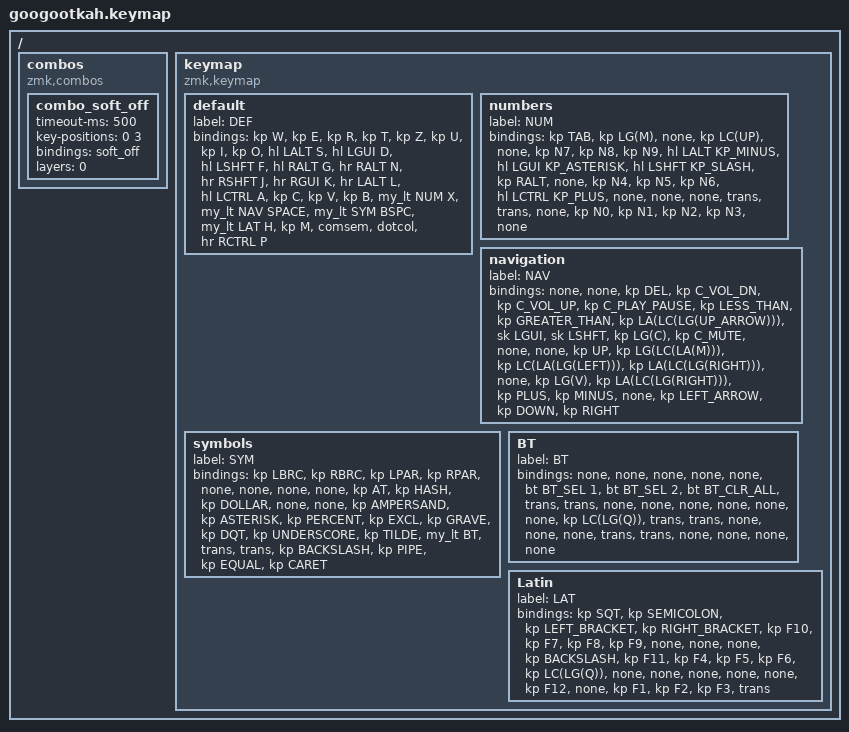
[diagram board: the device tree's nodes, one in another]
#include <behaviors.dtsi>
#include <dt-bindings/zmk/bt.h>
#include <dt-bindings/zmk/keys.h>
#include "googootkah.h"

/*               KEY POSITIONS
 *
 *           ╭──────────────╮          ╭──────────────╮ 
 *           │ 0   1   2   3│          │17  16  15  14│
 *      ╭────╯ 4   5   6   7╰────╮╭────╯21  20  19  18╰────╮
 *      │  8   9  10  11  12  13 ││ 27  26  25  24  23  22 │
 *      ╰────────────────────────╯╰────────────────────────╯
 */

/ {

    combos {
        compatible = "zmk,combos";

        combo_soft_off {
            timeout-ms = <500>;                 
            key-positions = <0 3>;           
            bindings = <&soft_off>;            
            layers = <0>;                      
        };
    };

    keymap {
        compatible = "zmk,keymap";

        default {
            label = "DEF";
            bindings = <
&kp W  &kp E  &kp R  &kp T  &kp Z  &kp U  &kp I  &kp O  &hl LALT S  &hl LGUI D  &hl LSHFT F  &hl RALT G  &hr RALT N  &hr RSHFT J  &hr RGUI K  &hr LALT L  &hl LCTRL A  &kp C  &kp V  &kp B  &my_lt NUM X  &my_lt NAV SPACE  &my_lt SYM BSPC  &my_lt LAT H  &kp M  &comsem  &dotcol  &hr RCTRL P
            >;
        };

        numbers {
            label = "NUM";
            bindings = <
&kp TAB  &kp LG(M)  &none  &kp LC(UP)  &none  &kp N7  &kp N8  &kp N9  &hl LALT KP_MINUS  &hl LGUI KP_ASTERISK  &hl LSHFT KP_SLASH  &kp RALT  &none  &kp N4  &kp N5  &kp N6  &hl LCTRL KP_PLUS  &none  &none  &none  &trans  &trans  &none  &kp N0  &kp N1  &kp N2  &kp N3  &none
            >;
        };

        navigation {
            label = "NAV";
            bindings = <
&none  &none  &kp DEL  &kp C_VOL_DN  &kp C_VOL_UP  &kp C_PLAY_PAUSE  &kp LESS_THAN  &kp GREATER_THAN  &kp LA(LC(LG(UP_ARROW)))  &sk LGUI  &sk LSHFT  &kp LG(C)  &kp C_MUTE  &none  &none  &kp UP  &kp LG(LC(LA(M)))  &kp LC(LA(LG(LEFT)))  &kp LA(LC(LG(RIGHT)))  &none  &kp LG(V)  &kp LA(LC(LG(RIGHT)))  &kp PLUS  &kp MINUS  &none  &kp LEFT_ARROW  &kp DOWN  &kp RIGHT
            >;
        };

        symbols {
            label = "SYM";
            bindings = <
&kp LBRC  &kp RBRC  &kp LPAR  &kp RPAR  &none  &none  &none  &none  &kp AT  &kp HASH  &kp DOLLAR  &none  &none  &kp AMPERSAND  &kp ASTERISK  &kp PERCENT  &kp EXCL  &kp GRAVE  &kp DQT  &kp UNDERSCORE  &kp TILDE  &my_lt BT  &trans  &trans  &kp BACKSLASH  &kp PIPE  &kp EQUAL  &kp CARET
            >;
        };

        BT {
            label = "BT";
            bindings = <
&none  &none  &none  &none  &none  &bt BT_SEL 1  &bt BT_SEL 2  &bt BT_CLR_ALL  &trans  &trans  &none  &none  &none  &none  &none  &none  &kp LC(LG(Q))  &trans  &trans  &none  &none  &none  &trans  &trans  &none  &none  &none  &none
            >;
        };

        Latin {
            label = "LAT";
            bindings = <
&kp SQT  &kp SEMICOLON  &kp LEFT_BRACKET  &kp RIGHT_BRACKET  &kp F10  &kp F7  &kp F8  &kp F9  &none  &none  &none  &kp BACKSLASH  &kp F11  &kp F4  &kp F5  &kp F6  &kp LC(LG(Q))  &none  &none  &none  &none  &none  &kp F12  &none  &kp F1  &kp F2  &kp F3  &trans
            >;
        };
    };
};
